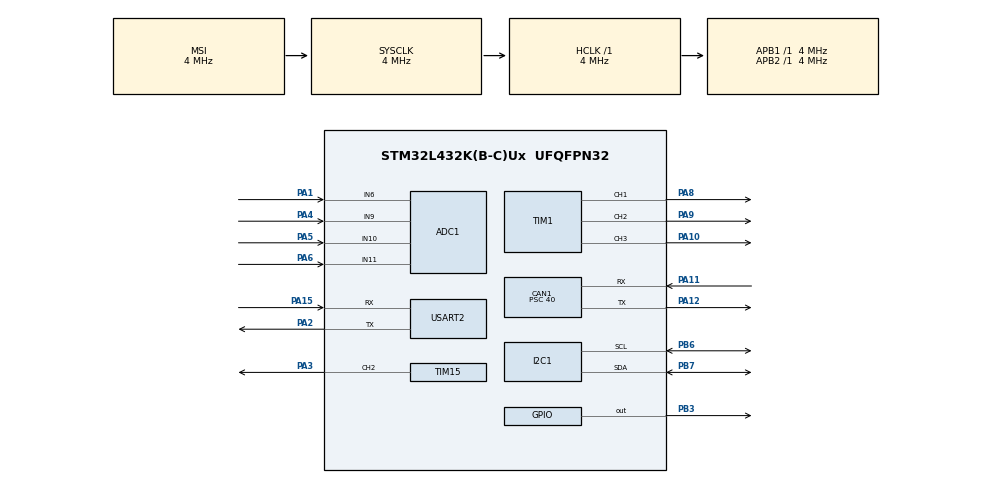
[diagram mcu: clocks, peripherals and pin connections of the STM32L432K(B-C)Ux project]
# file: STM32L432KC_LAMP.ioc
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ADC1.Channel-0\#ChannelRegularConversion=ADC_CHANNEL_6
ADC1.NbrOfConversionFlag=1
ADC1.OffsetNumber-0\#ChannelRegularConversion=ADC_OFFSET_NONE
ADC1.Rank-0\#ChannelRegularConversion=1
ADC1.SamplingTime-0\#ChannelRegularConversion=ADC_SAMPLETIME_2CYCLES_5
ADC1.master=1
CAN1.BS1=CAN_BS1_2TQ
CAN1.BS2=CAN_BS2_2TQ
CAN1.CalculateBaudRate=20000
CAN1.CalculateTimeBit=50000.00
CAN1.CalculateTimeQuantum=10000.0
CAN1.Prescaler=40
CAN1.SJW=CAN_SJW_1TQ
DAC1.DAC_Channel-DAC_OUT2=DAC_CHANNEL_2
Dma.Request0=USART2_RX
Dma.Request1=USART2_TX
Dma.USART2_RX.0.Direction=DMA_PERIPH_TO_MEMORY
Dma.USART2_RX.0.Instance=DMA1_Channel6
Dma.USART2_RX.0.MemDataAlignment=DMA_MDATAALIGN_BYTE
Dma.USART2_RX.0.MemInc=DMA_MINC_ENABLE
Dma.USART2_RX.0.Mode=DMA_NORMAL
Dma.USART2_RX.0.PeriphDataAlignment=DMA_PDATAALIGN_BYTE
Dma.USART2_RX.0.PeriphInc=DMA_PINC_DISABLE
Dma.USART2_RX.0.Priority=DMA_PRIORITY_LOW
Dma.USART2_TX.1.Direction=DMA_MEMORY_TO_PERIPH
Dma.USART2_TX.1.Instance=DMA1_Channel7
Dma.USART2_TX.1.MemDataAlignment=DMA_MDATAALIGN_BYTE
Dma.USART2_TX.1.MemInc=DMA_MINC_ENABLE
Dma.USART2_TX.1.Mode=DMA_NORMAL
Dma.USART2_TX.1.PeriphDataAlignment=DMA_PDATAALIGN_BYTE
Dma.USART2_TX.1.PeriphInc=DMA_PINC_DISABLE
Dma.USART2_TX.1.Priority=DMA_PRIORITY_LOW
Mcu.Family=STM32L4
Mcu.Name=STM32L432K(B-C)Ux
Mcu.Package=UFQFPN32
NVIC.CAN1_RX0_IRQn=true\:0\:0\:false\:false\:true\:true\:true
NVIC.CAN1_TX_IRQn=true\:0\:0\:false\:false\:true\:true\:true
NVIC.DMA1_Channel6_IRQn=true\:0\:0\:false\:false\:true\:false\:true
NVIC.DMA1_Channel7_IRQn=true\:0\:0\:false\:false\:true\:false\:true
NVIC.PriorityGroup=NVIC_PRIORITYGROUP_4
NVIC.TIM6_DAC_IRQn=true\:0\:0\:false\:false\:true\:false\:true
NVIC.TimeBase=TIM6_DAC_IRQn
NVIC.TimeBaseIP=TIM6
PA0.Mode=HSE-External-Clock-Source-for-LittleOrca
PA0.Signal=RCC_CK_IN
PA1.Signal=ADCx_IN6
PA10.Signal=S_TIM1_CH3
PA11.Mode=CAN_Activate
PA11.Signal=CAN1_RX
PA12.Mode=CAN_Activate
PA12.Signal=CAN1_TX
PA15\ (JTDI).Mode=Asynchronous
PA15\ (JTDI).Signal=USART2_RX
PA2.Mode=Asynchronous
PA2.Signal=USART2_TX
PA3.Signal=S_TIM15_CH2
PA4.Signal=SharedAnalog_PA4
PA5.Signal=SharedAnalog_PA5
PA6.Signal=ADCx_IN11
PA8.Signal=S_TIM1_CH1
PA9.Signal=S_TIM1_CH2
PB3\ (JTDO-TRACESWO).Signal=GPIO_Output
PB6.Mode=I2C
PB6.Signal=I2C1_SCL
PB7.Mode=I2C
PB7.Signal=I2C1_SDA
PC14-OSC32_IN\ (PC14).Mode=LSE-External-Oscillator
PC14-OSC32_IN\ (PC14).Signal=RCC_OSC32_IN
PC15-OSC32_OUT\ (PC15).Mode=LSE-External-Oscillator
PC15-OSC32_OUT\ (PC15).Signal=RCC_OSC32_OUT
ProjectManager.HeapSize=0x200
ProjectManager.StackSize=0x400
ProjectManager.TargetToolchain=STM32CubeIDE
RCC.ADCFreq_Value=32000000
RCC.AHBFreq_Value=4000000
RCC.APB1Freq_Value=4000000
RCC.APB1TimFreq_Value=4000000
RCC.APB2Freq_Value=4000000
RCC.APB2TimFreq_Value=4000000
RCC.CortexFreq_Value=4000000
RCC.HCLKFreq_Value=4000000
RCC.HSE_VALUE=16000000
RCC.HSI48_VALUE=48000000
RCC.HSI_VALUE=16000000
RCC.MSI_VALUE=4000000
RCC.PLLN=40
RCC.PLLSAI1N=16
RCC.SYSCLKFreq_VALUE=4000000
RCC.USART2CLockSelection=RCC_USART2CLKSOURCE_SYSCLK
RCC.USBFreq_Value=32000000
RCC.VCOOutputFreq_Value=160000000
SH.ADCx_IN11.0=ADC1_IN11,IN11-Single-Ended
SH.ADCx_IN6.0=ADC1_IN6,IN6-Single-Ended
SH.S_TIM15_CH2.0=TIM15_CH2,PWM Generation2 CH2
SH.S_TIM1_CH1.0=TIM1_CH1,PWM Generation1 CH1
SH.S_TIM1_CH2.0=TIM1_CH2,PWM Generation2 CH2
SH.S_TIM1_CH3.0=TIM1_CH3,PWM Generation3 CH3
SH.SharedAnalog_PA4.0=ADC1_IN9,IN9-Single-Ended
SH.SharedAnalog_PA4.1=DAC1_OUT1,DAC_OUT1
SH.SharedAnalog_PA5.0=ADC1_IN10,IN10-Single-Ended
SH.SharedAnalog_PA5.1=DAC1_OUT2,DAC_OUT2
TIM1.Channel-PWM\ Generation1\ CH1=TIM_CHANNEL_1
TIM1.Channel-PWM\ Generation2\ CH2=TIM_CHANNEL_2
TIM1.Channel-PWM\ Generation3\ CH3=TIM_CHANNEL_3
TIM15.Channel-PWM\ Generation2\ CH2=TIM_CHANNEL_2
USART2.AutoBaudRateEnableParam=UART_ADVFEATURE_AUTOBAUDRATE_DISABLE
USART2.Parity=PARITY_NONE
USART2.StopBits=STOPBITS_1
USART2.VirtualMode-Asynchronous=VM_ASYNC
USART2.WordLength=WORDLENGTH_8B
VP_SYS_VS_tim6.Mode=TIM6
board=custom

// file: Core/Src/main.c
/* USER CODE BEGIN Header */
/**
  ******************************************************************************
  * @file           : main.c
  * @brief          : Main program body
  ******************************************************************************
  * @attention
  *
  * <h2><center>&copy; Copyright (c) 2021 STMicroelectronics.
  * All rights reserved.</center></h2>
  *
  * This software component is licensed by ST under Ultimate Liberty license
  * SLA0044, the "License"; You may not use this file except in compliance with
  * the License. You may obtain a copy of the License at:
  *                             www.st.com/SLA0044
  *
  ******************************************************************************
  */
/* USER CODE END Header */
#include "main.h"
#include "adc.h"
#include "can.h"
#include "dac.h"
#include "dma.h"
#include "i2c.h"
#include "tim.h"
#include "usart.h"
#include "gpio.h"

/* USER CODE BEGIN Includes */
#include <string.h>
#include <application.h>
#include <AS7341.h>
#include <MCP9600.h>
#include <PCA9685.h>
/* USER CODE END Includes */

void SystemClock_Config(void);

int main(void)
{

  /* MCU Configuration--------------------------------------------------------*/

  /* Reset of all peripherals, Initializes the Flash interface and the Systick. */
  HAL_Init();

  /* Configure the system clock */
  SystemClock_Config();

  /* Initialize all configured peripherals */
  MX_GPIO_Init();
  MX_DMA_Init();
  MX_I2C1_Init();
  MX_USART2_UART_Init();
  MX_CAN1_Init();
  MX_TIM1_Init();
  MX_ADC1_Init();
  MX_TIM15_Init();
  MX_DAC1_Init();

  /* Infinite loop */
  /* USER CODE BEGIN WHILE */
  while (1)
  {
	  programStart();
    /* USER CODE END WHILE */

  }
}

void SystemClock_Config(void)
{
  RCC_OscInitTypeDef RCC_OscInitStruct = {0};
  RCC_ClkInitTypeDef RCC_ClkInitStruct = {0};
  RCC_PeriphCLKInitTypeDef PeriphClkInit = {0};

  /** Configure LSE Drive Capability
  */
  HAL_PWR_EnableBkUpAccess();
  __HAL_RCC_LSEDRIVE_CONFIG(RCC_LSEDRIVE_LOW);
  /** Initializes the RCC Oscillators according to the specified parameters
  * in the RCC_OscInitTypeDef structure.
  */
  RCC_OscInitStruct.OscillatorType = RCC_OSCILLATORTYPE_LSE|RCC_OSCILLATORTYPE_MSI;
  RCC_OscInitStruct.LSEState = RCC_LSE_ON;
  RCC_OscInitStruct.MSIState = RCC_MSI_ON;
  RCC_OscInitStruct.MSICalibrationValue = 0;
  RCC_OscInitStruct.MSIClockRange = RCC_MSIRANGE_6;
  RCC_OscInitStruct.PLL.PLLState = RCC_PLL_NONE;
  if (HAL_RCC_OscConfig(&RCC_OscInitStruct) != HAL_OK)
  {
    Error_Handler();
  }
  /** Initializes the CPU, AHB and APB buses clocks
  */
  RCC_ClkInitStruct.ClockType = RCC_CLOCKTYPE_HCLK|RCC_CLOCKTYPE_SYSCLK
                              |RCC_CLOCKTYPE_PCLK1|RCC_CLOCKTYPE_PCLK2;
  RCC_ClkInitStruct.SYSCLKSource = RCC_SYSCLKSOURCE_MSI;
  RCC_ClkInitStruct.AHBCLKDivider = RCC_SYSCLK_DIV1;
  RCC_ClkInitStruct.APB1CLKDivider = RCC_HCLK_DIV1;
  RCC_ClkInitStruct.APB2CLKDivider = RCC_HCLK_DIV1;

  if (HAL_RCC_ClockConfig(&RCC_ClkInitStruct, FLASH_LATENCY_0) != HAL_OK)
  {
    Error_Handler();
  }
  PeriphClkInit.PeriphClockSelection = RCC_PERIPHCLK_USART2|RCC_PERIPHCLK_I2C1
                              |RCC_PERIPHCLK_ADC;
  PeriphClkInit.Usart2ClockSelection = RCC_USART2CLKSOURCE_SYSCLK;
  PeriphClkInit.I2c1ClockSelection = RCC_I2C1CLKSOURCE_PCLK1;
  PeriphClkInit.AdcClockSelection = RCC_ADCCLKSOURCE_PLLSAI1;
  PeriphClkInit.PLLSAI1.PLLSAI1Source = RCC_PLLSOURCE_MSI;
  PeriphClkInit.PLLSAI1.PLLSAI1M = 1;
  PeriphClkInit.PLLSAI1.PLLSAI1N = 16;
  PeriphClkInit.PLLSAI1.PLLSAI1P = RCC_PLLP_DIV7;
  PeriphClkInit.PLLSAI1.PLLSAI1Q = RCC_PLLQ_DIV2;
  PeriphClkInit.PLLSAI1.PLLSAI1R = RCC_PLLR_DIV2;
  PeriphClkInit.PLLSAI1.PLLSAI1ClockOut = RCC_PLLSAI1_ADC1CLK;
  if (HAL_RCCEx_PeriphCLKConfig(&PeriphClkInit) != HAL_OK)
  {
    Error_Handler();
  }
  /** Configure the main internal regulator output voltage
  */
  if (HAL_PWREx_ControlVoltageScaling(PWR_REGULATOR_VOLTAGE_SCALE1) != HAL_OK)
  {
    Error_Handler();
  }
  /** Enable MSI Auto calibration
  */
  HAL_RCCEx_EnableMSIPLLMode();
}

 /**
  * @brief  Period elapsed callback in non blocking mode
  * @note   This function is called  when TIM6 interrupt took place, inside
  * HAL_TIM_IRQHandler(). It makes a direct call to HAL_IncTick() to increment
  * a global variable "uwTick" used as application time base.
  * @param  htim : TIM handle
  * @retval None
  */
void HAL_TIM_PeriodElapsedCallback(TIM_HandleTypeDef *htim)
{
  if (htim->Instance == TIM6) {
    HAL_IncTick();
  }
}

void Error_Handler(void)
{
  __disable_irq();
  while (1)
  {
  }
}

/************************ (C) COPYRIGHT STMicroelectronics *****END OF FILE****/
